# FPE register map
Vendor: Texas Instruments
Peripheral module from a debugger description file (folder UCD3138R032RJA).
Registers are 32-bit, access per field, reset 0x0 unless marked. A register's access mark holds for its fields unless they carry their own. Offsets are as the file gives them; lines under a group give offsets from that group; [hi:lo] are bit positions; {n}, {i} and the like mark numbered series; 'fields as' and 'values as' point back to an identical list; <NAME> marks a mode.

## FPE
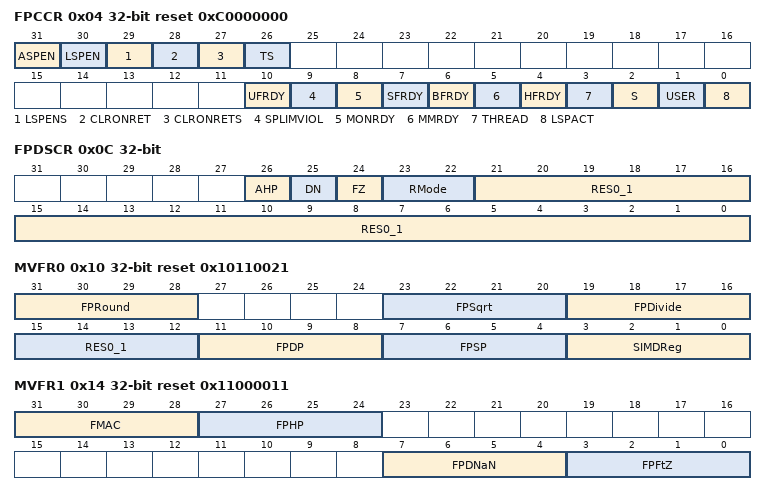
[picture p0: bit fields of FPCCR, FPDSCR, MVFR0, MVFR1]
0x04 FPCCR reset 0xC0000000 — Holds control data for the Floating-point extension
  [31] ASPEN rw — When this bit is set to 1, execution of a floating-point instruction sets the CONTROL.FPCA bit to 1
  [30] LSPEN rw — Enables lazy context save of floating-point state
  [29] LSPENS rw — This bit controls whether the LSPEN bit is writeable from the Non-secure state
  [28] CLRONRET rw — Clear floating-point caller saved registers on exception return
  [27] CLRONRETS rw — This bit controls whether the CLRONRET bit is writeable from the Non-secure state
  [26] TS rw — Treat floating-point registers as Secure enable
  [10] UFRDY rw — Indicates whether the software executing when the PE allocated the floating-point stack frame was able to set the UsageFault exception to pending
  [9] SPLIMVIOL rw — This bit is banked between the Security states and indicates whether the floating-point context violates the stack pointer limit that was active when lazy state preservation was activated. SPLIMVIOL modifies the lazy floating-point state preservation behavior
  [8] MONRDY rw — Indicates whether the software executing when the PE allocated the floating-point stack frame was able to set the DebugMonitor exception to pending
  [7] SFRDY rw — Indicates whether the software executing when the PE allocated the floating-point stack frame was able to set the SecureFault exception to pending. This bit is only present in the Secure version of the register, and behaves as RAZ/WI when accessed from the Non-secure state
  [6] BFRDY rw — Indicates whether the software executing when the PE allocated the floating-point stack frame was able to set the BusFault exception to pending
  [5] MMRDY rw — Indicates whether the software executing when the PE allocated the floating-point stack frame was able to set the MemManage exception to pending
  [4] HFRDY rw — Indicates whether the software executing when the PE allocated the floating-point stack frame was able to set the HardFault exception to pending
  [3] THREAD rw — Indicates the PE mode when it allocated the floating-point stack frame
  [2] S rw — Security status of the floating-point context. This bit is only present in the Secure version of the register, and behaves as RAZ/WI when accessed from the Non-secure state. This bit is updated whenever lazy state preservation is activated, or when a floating-point instruction is executed
  [1] USER rw — Indicates the privilege level of the software executing when the PE allocated the floating-point stack frame
  [0] LSPACT rw — Indicates whether lazy preservation of the floating-point state is active
0x08 FPCAR — Holds the location of the unpopulated floating-point register space allocated on an exception stack frame
  [31:3] ADDRESS rw — The location of the unpopulated floating-point register space allocated on an exception stack frame
0x0C FPDSCR — Holds the default values for the floating-point status control data that the PE assigns to the FPSCR when it creates a new floating-point context
  [26] AHP rw — Default value for FPSCR.AHP
  [25] DN rw — Default value for FPSCR.DN
  [24] FZ rw — Default value for FPSCR.FZ
  [23:22] RMode rw — Default value for FPSCR.RMode
  [21:0] RES0_1 ro — Reserved, RES0
0x10 MVFR0 ro reset 0x10110021 — Describes the features provided by the Floating-point Extension
  [31:28] FPRound — Indicates the rounding modes supported by the FP Extension
  [23:20] FPSqrt — Indicates the support for FP square root operations
  [19:16] FPDivide — Indicates the support for FP divide operations
  [15:12] RES0_1 — Reserved, RES0
  [11:8] FPDP — Indicates support for FP double-precision operations
  [7:4] FPSP — Indicates support for FP single-precision operations
  [3:0] SIMDReg — Indicates size of FP register file
0x14 MVFR1 ro reset 0x11000011 — Describes the features provided by the Floating-point Extension
  [31:28] FMAC — Indicates whether the FP Extension implements the fused multiply accumulate instructions
  [27:24] FPHP — Indicates whether the FP Extension implements half-precision FP conversion instructions
  [7:4] FPDNaN — Indicates whether the FP hardware implementation supports NaN propagation
  [3:0] FPFtZ — Indicates whether subnormals are always flushed-to-zero
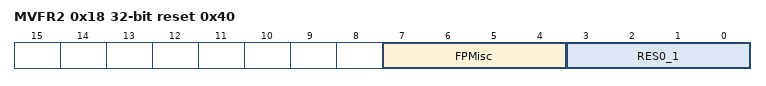
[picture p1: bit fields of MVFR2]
0x18 MVFR2 ro reset 0x40 — Describes the features provided by the Floating-point Extension
  [7:4] FPMisc — Indicates support for miscellaneous FP features
  [3:0] RES0_1 — Reserved, RES0
